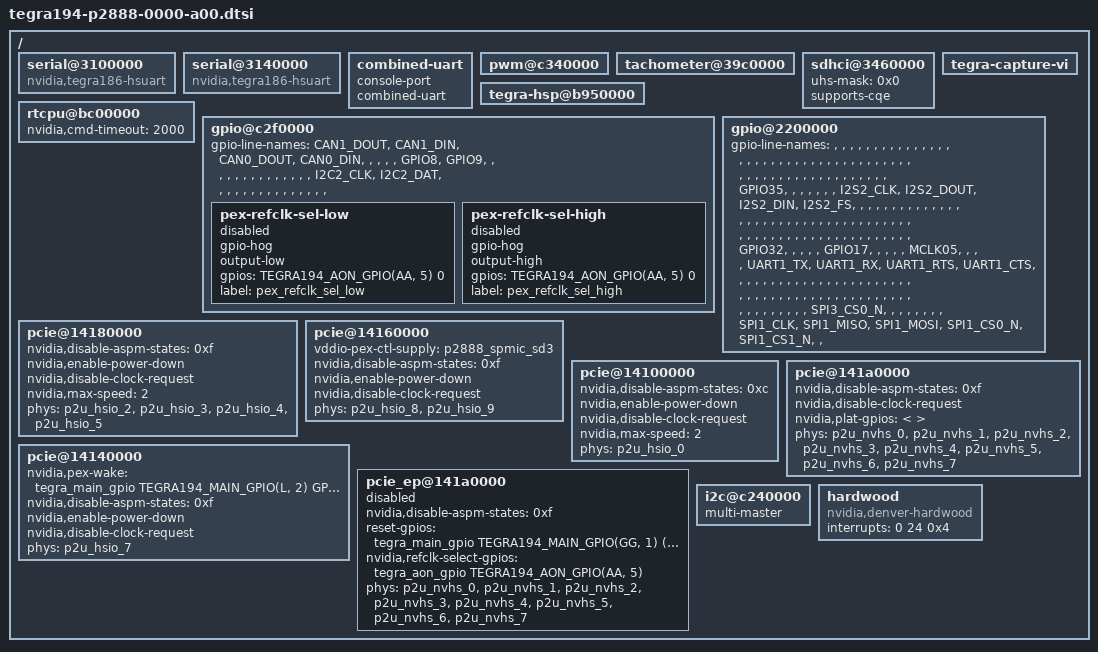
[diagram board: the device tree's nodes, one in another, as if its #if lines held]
/*
 * Copyright (c) 2017-2020, NVIDIA CORPORATION.  All rights reserved.
 *
 * This program is free software; you can redistribute it and/or modify it
 * under the terms and conditions of the GNU General Public License,
 * version 2, as published by the Free Software Foundation.
 *
 * This program is distributed in the hope it will be useful, but WITHOUT
 * ANY WARRANTY; without even the implied warranty of MERCHANTABILITY or
 * FITNESS FOR A PARTICULAR PURPOSE.  See the GNU General Public License for
 * more details.
 *
 * You should have received a copy of the GNU General Public License
 * along with this program.  If not, see <http://www.gnu.org/licenses/>.
 */

/*
 * T194 P2888-0000 common DTSI file.
 */

#include <t19x-common-modules/tegra194-cvm-p2888-0000-a00.dtsi>
#include "tegra194-eeprom-manager-p2888-0000.dtsi"
#include "tegra194-powermon-p2888.dtsi"
#include <dt-bindings/pinctrl/pinctrl-tegra.h>

/ {
/*
        pinmux@2430000 {
		pinctrl-names = "default", "drive", "unused";
		pinctrl-0 = <&pinmux_default>;
			
		pinmux_default: common {
		                dp_aux_ch0_hpd_pm0 {

                                nvidia,pins = "dp_aux_ch0_hpd_pm0";

                                nvidia,function = "rsvd1";

                                nvidia,pull = <TEGRA_PIN_PULL_NONE>;

                                nvidia,tristate = <TEGRA_PIN_ENABLE>;

                                nvidia,enable-input = <TEGRA_PIN_ENABLE>;

                                nvidia,io-high-voltage = <TEGRA_PIN_DISABLE>;

                                nvidia,lpdr = <TEGRA_PIN_DISABLE>;

                        };

                        dp_aux_ch1_hpd_pm1 {

                                nvidia,pins = "dp_aux_ch1_hpd_pm1";

                                nvidia,function = "rsvd1";

                                nvidia,pull = <TEGRA_PIN_PULL_NONE>;

                                nvidia,tristate = <TEGRA_PIN_ENABLE>;

                                nvidia,enable-input = <TEGRA_PIN_ENABLE>;

                                nvidia,io-high-voltage = <TEGRA_PIN_DISABLE>;

                                nvidia,lpdr = <TEGRA_PIN_DISABLE>;

                        };
                                               soc_gpio04_pp4 {

                                nvidia,pins = "soc_gpio04_pp4";

                                nvidia,function = "rsvd0";

                                nvidia,pull = <TEGRA_PIN_PULL_UP>;

                                nvidia,tristate = <TEGRA_PIN_ENABLE>;

                                nvidia,enable-input = <TEGRA_PIN_DISABLE>;

                                nvidia,lpdr = <TEGRA_PIN_DISABLE>;

                        };

                        soc_gpio54_pn1 {

                                nvidia,pins = "soc_gpio54_pn1";

                                nvidia,function = "rsvd0";

                                nvidia,pull = <TEGRA_PIN_PULL_UP>;

                                nvidia,tristate = <TEGRA_PIN_ENABLE>;

                                nvidia,enable-input = <TEGRA_PIN_ENABLE>;

                                nvidia,lpdr = <TEGRA_PIN_DISABLE>;

                        };

                        dap3_din_pt3 {

                                nvidia,pins = "dap3_din_pt3";

                                nvidia,function = "rsvd2";

                                nvidia,pull = <TEGRA_PIN_PULL_UP>;

                                nvidia,tristate = <TEGRA_PIN_ENABLE>;

                                nvidia,enable-input = <TEGRA_PIN_ENABLE>;

                                nvidia,lpdr = <TEGRA_PIN_DISABLE>;

                        };

                       

                        soc_gpio21_pq1 {

                                nvidia,pins = "soc_gpio21_pq1";

                                nvidia,function = "rsvd0";

                                nvidia,pull = <TEGRA_PIN_PULL_UP>;

                                nvidia,tristate = <TEGRA_PIN_ENABLE>;

                                nvidia,enable-input = <TEGRA_PIN_ENABLE>;

                                nvidia,lpdr = <TEGRA_PIN_DISABLE>;

                        };
                          dap1_sclk_ps0 {

                                nvidia,pins = "dap1_sclk_ps0";

                                nvidia,function = "i2s1";

                                nvidia,pull = <TEGRA_PIN_PULL_NONE>;

                                nvidia,tristate = <TEGRA_PIN_DISABLE>;

                                nvidia,enable-input = <TEGRA_PIN_ENABLE>;

                                nvidia,lpdr = <TEGRA_PIN_DISABLE>;

                        };

 

                        dap1_dout_ps1 {

                                nvidia,pins = "dap1_dout_ps1";

                                nvidia,function = "i2s1";

                                nvidia,pull = <TEGRA_PIN_PULL_NONE>;

                                nvidia,tristate = <TEGRA_PIN_DISABLE>;

                                nvidia,enable-input = <TEGRA_PIN_DISABLE>;

                                nvidia,lpdr = <TEGRA_PIN_DISABLE>;

                        };

 

                        dap1_din_ps2 {

                                nvidia,pins = "dap1_din_ps2";

                                nvidia,function = "i2s1";

                                nvidia,pull = <TEGRA_PIN_PULL_DOWN>;

                                nvidia,tristate = <TEGRA_PIN_ENABLE>;

                                nvidia,enable-input = <TEGRA_PIN_ENABLE>;

                                nvidia,lpdr = <TEGRA_PIN_DISABLE>;

                        };

 

                        dap1_fs_ps3 {

                                nvidia,pins = "dap1_fs_ps3";

                                nvidia,function = "i2s1";

                                nvidia,pull = <TEGRA_PIN_PULL_NONE>;

                                nvidia,tristate = <TEGRA_PIN_DISABLE>;

                                nvidia,enable-input = <TEGRA_PIN_ENABLE>;

                                nvidia,lpdr = <TEGRA_PIN_DISABLE>;

                        };
                         can1_dout_paa0 {

                                nvidia,pins = "can1_dout_paa0";

                                nvidia,function = "can1";

                                nvidia,pull = <TEGRA_PIN_PULL_NONE>;

                                nvidia,tristate = <TEGRA_PIN_DISABLE>;

                                nvidia,enable-input = <TEGRA_PIN_DISABLE>;

                        };

 

                        can1_din_paa1 {

                                nvidia,pins = "can1_din_paa1";

                                nvidia,function = "can1";

                                nvidia,pull = <TEGRA_PIN_PULL_NONE>;

                                nvidia,tristate = <TEGRA_PIN_ENABLE>;

                                nvidia,enable-input = <TEGRA_PIN_ENABLE>;

                        };

 

                        can0_dout_paa2 {

                                nvidia,pins = "can0_dout_paa2";

                                nvidia,function = "can0";

                                nvidia,pull = <TEGRA_PIN_PULL_NONE>;

                                nvidia,tristate = <TEGRA_PIN_DISABLE>;

                                nvidia,enable-input = <TEGRA_PIN_DISABLE>;

                        };

 

                        can0_din_paa3 {

                                nvidia,pins = "can0_din_paa3";

                                nvidia,function = "can0";

                                nvidia,pull = <TEGRA_PIN_PULL_NONE>;

                                nvidia,tristate = <TEGRA_PIN_ENABLE>;

                                nvidia,enable-input = <TEGRA_PIN_ENABLE>;

                        };
                        can0_wake_paa6 {

                                nvidia,pins = "can0_wake_paa6";

                                nvidia,function = "rsvd0";

                                nvidia,pull = <TEGRA_PIN_PULL_DOWN>;

                                nvidia,tristate = <TEGRA_PIN_ENABLE>;

                                nvidia,enable-input = <TEGRA_PIN_ENABLE>;

                        };
                        
                        gen1_i2c_scl_pi3 {

                                nvidia,pins = "gen1_i2c_scl_pi3";

                                nvidia,function = "i2c1";

                                nvidia,pull = <TEGRA_PIN_PULL_NONE>;

                                nvidia,tristate = <TEGRA_PIN_DISABLE>;

                                nvidia,enable-input = <TEGRA_PIN_ENABLE>;

                                nvidia,io-high-voltage = <TEGRA_PIN_DISABLE>;

                                nvidia,lpdr = <TEGRA_PIN_DISABLE>;

                        };

 

                        gen1_i2c_sda_pi4 {

                                nvidia,pins = "gen1_i2c_sda_pi4";

                                nvidia,function = "i2c1";

                                nvidia,pull = <TEGRA_PIN_PULL_NONE>;

                                nvidia,tristate = <TEGRA_PIN_DISABLE>;

                                nvidia,enable-input = <TEGRA_PIN_ENABLE>;

                                nvidia,io-high-voltage = <TEGRA_PIN_DISABLE>;

                                nvidia,lpdr = <TEGRA_PIN_DISABLE>;

                        };
			spi1_sck_pz3 {
				nvidia,pins = "spi1_sck_pz3";
				nvidia,function = "spi1";
				nvidia,lpdr = <0x0>;
				nvidia,enable-input = <0x1>;
				nvidia,tristate = <0x0>;
				nvidia,pull = <0x2>;
			};

			spi1_miso_pz4 {
				nvidia,pins = "spi1_miso_pz4";
				nvidia,function = "spi1";
				nvidia,lpdr = <0x0>;
				nvidia,enable-input = <0x1>;
				nvidia,tristate = <0x0>;
				nvidia,pull = <0x2>;
			};

			spi1_mosi_pz5 {
				nvidia,pins = "spi1_mosi_pz5";
				nvidia,function = "spi1";
				nvidia,lpdr = <0x0>;
				nvidia,enable-input = <0x1>;
				nvidia,tristate = <0x0>;
				nvidia,pull = <0x2>;
			};

			spi1_cs0_pz6 {
				nvidia,pins = "spi1_cs0_pz6";
				nvidia,function = "spi1";
				nvidia,lpdr = <0x0>;
				nvidia,enable-input = <0x1>;
				nvidia,tristate = <0x0>;
				nvidia,pull = <0x2>;
			};

			spi1_cs1_pz7 {
				nvidia,pins = "spi1_cs1_pz7";
				nvidia,function = "spi1";
				nvidia,lpdr = <0x0>;
				nvidia,enable-input = <0x1>;
				nvidia,tristate = <0x0>;
				nvidia,pull = <0x2>;
			};

			can1_stb_pbb0 {
				nvidia,pins = "can1_stb_pbb0";
				nvidia,function = "rsvd0";
				nvidia,pull = <TEGRA_PIN_PULL_NONE>;
				nvidia,tristate = <TEGRA_PIN_ENABLE>;
				nvidia,enable-input = <TEGRA_PIN_ENABLE>;
			};
			
			can0_en_paa5 {
				nvidia,pins = "can0_en_paa5";
				nvidia,function = "rsvd0";
				nvidia,pull = <TEGRA_PIN_PULL_NONE>;
				nvidia,tristate = <TEGRA_PIN_ENABLE>;
				nvidia,enable-input = <TEGRA_PIN_ENABLE>;
			};
			
			can1_wake_pbb2 {
				nvidia,pins = "can1_wake_pbb2";
				nvidia,function = "rsvd0";
				nvidia,pull = <TEGRA_PIN_PULL_NONE>;
				nvidia,tristate = <TEGRA_PIN_ENABLE>;
				nvidia,enable-input = <TEGRA_PIN_ENABLE>;
			};
			

			soc_gpio33_pt0 {
				nvidia,pins = "soc_gpio33_pt0";
				nvidia,function = "rsvd0";
				nvidia,pull = <TEGRA_PIN_PULL_UP>;
				nvidia,tristate = <TEGRA_PIN_ENABLE>;
				nvidia,enable-input = <TEGRA_PIN_ENABLE>;
				nvidia,lpdr = <TEGRA_PIN_DISABLE>;
			};
			
			
			dap3_fs_pt4 {
				nvidia,pins = "dap3_fs_pt4";
				nvidia,function = "rsvd2";
				nvidia,pull = <TEGRA_PIN_PULL_UP>;
				nvidia,tristate = <TEGRA_PIN_ENABLE>;
				nvidia,enable-input = <TEGRA_PIN_ENABLE>;
				nvidia,lpdr = <TEGRA_PIN_DISABLE>;
			};
			
			soc_gpio40_pq4 {
				nvidia,pins = "soc_gpio40_pq4";
				nvidia,function = "rsvd2";
				nvidia,pull = <TEGRA_PIN_PULL_UP>;
				nvidia,tristate = <TEGRA_PIN_ENABLE>;
				nvidia,enable-input = <TEGRA_PIN_ENABLE>;
				nvidia,io-high-voltage = <TEGRA_PIN_DISABLE>;
				nvidia,lpdr = <TEGRA_PIN_DISABLE>;
			};
			
			soc_gpio53_pn0 {
				nvidia,pins = "soc_gpio53_pn0";
				nvidia,function = "rsvd0";
				nvidia,pull = <TEGRA_PIN_PULL_DOWN>;
				nvidia,tristate = <TEGRA_PIN_DISABLE>;
				nvidia,enable-input = <TEGRA_PIN_ENABLE>;
				nvidia,lpdr = <TEGRA_PIN_DISABLE>;
			};
			
			safe_state_pee0 {
				nvidia,pins = "safe_state_pee0";
				nvidia,function = "rsvd1";
				nvidia,pull = <TEGRA_PIN_PULL_UP>;
				nvidia,tristate = <TEGRA_PIN_ENABLE>;
				nvidia,enable-input = <TEGRA_PIN_ENABLE>;
				nvidia,io-high-voltage = <TEGRA_PIN_DISABLE>;
				nvidia,lpdr = <TEGRA_PIN_DISABLE>;
			};
			
			
			soc_gpio50_pm5 {
				nvidia,pins = "soc_gpio50_pm5";
				nvidia,function = "rsvd0";
				nvidia,pull = <TEGRA_PIN_PULL_UP>;
				nvidia,tristate = <TEGRA_PIN_ENABLE>;
				nvidia,enable-input = <TEGRA_PIN_ENABLE>;
				nvidia,lpdr = <TEGRA_PIN_DISABLE>;
			};
			
		        usb_vbus_en1_pz2 {
				nvidia,pins = "usb_vbus_en1_pz2";
				nvidia,function = "rsvd1";
				nvidia,pull = <TEGRA_PIN_PULL_NONE>;
				nvidia,tristate = <TEGRA_PIN_ENABLE>;
				nvidia,enable-input = <TEGRA_PIN_ENABLE>;
				nvidia,io-high-voltage = <TEGRA_PIN_DISABLE>;
				nvidia,lpdr = <TEGRA_PIN_DISABLE>;
			};

			soc_gpio02_pg2 {
				nvidia,pins = "soc_gpio02_pg2";
				nvidia,function = "rsvd0";
				nvidia,pull = <TEGRA_PIN_PULL_UP>;
				nvidia,tristate = <TEGRA_PIN_ENABLE>;
				nvidia,enable-input = <TEGRA_PIN_ENABLE>;
				nvidia,lpdr = <TEGRA_PIN_DISABLE>;
			};
			
			dp_aux_ch3_hpd_pm3 {
				nvidia,pins = "dp_aux_ch3_hpd_pm3";
				nvidia,function = "rsvd2";
				nvidia,pull = <TEGRA_PIN_PULL_UP>;
				nvidia,tristate = <TEGRA_PIN_ENABLE>;
				nvidia,enable-input = <TEGRA_PIN_ENABLE>;
				nvidia,io-high-voltage = <TEGRA_PIN_DISABLE>;
			};
			
			soc_gpio43_pq7 {
				nvidia,pins = "soc_gpio43_pq7";
				nvidia,function = "rsvd2";
				nvidia,pull = <TEGRA_PIN_PULL_UP>;
				nvidia,tristate = <TEGRA_PIN_ENABLE>;
				nvidia,enable-input = <TEGRA_PIN_ENABLE>;
				nvidia,io-high-voltage = <TEGRA_PIN_DISABLE>;
				nvidia,lpdr = <TEGRA_PIN_DISABLE>;
			};

		};
	};
	
	*/
	serial@3100000 {
		compatible = "nvidia,tegra186-hsuart";
		status = "okay";
	};

	serial@3140000 {
		compatible = "nvidia,tegra186-hsuart";
		status = "okay";
	};

	combined-uart {
		console-port;
		combined-uart;
		status = "okay";
	};

	pwm@c340000 {
		status = "okay";
	};

	tachometer@39c0000 {
		status = "okay";
	};

	sdhci@3460000 {
		uhs-mask = <0x0>;
#if TEGRA_SDMMC_VERSION >= DT_VERSION_2
		supports-cqe;
#else
		nvidia,enable-hwcq;
#endif
		status = "okay";
	};

	tegra-hsp@b950000 {
		status = "okay";
	};

	rtcpu@bc00000 {
		status = "okay";
		nvidia,cmd-timeout = <2000>;
	};

	tegra-capture-vi {
		status = "okay";
	};

#if TEGRA_PCIE_VERSION < DT_VERSION_2
	gpio@c2f0000 {
		/* gpio-name for 40-pin header, gpio-name given as COL(10) x ROW(4) */
		gpio-line-names = "CAN1_DOUT",   "CAN1_DIN",     "CAN0_DOUT",     "CAN0_DIN",     "",     "",     "",     "",     "GPIO8",     "GPIO9",
		"",     "",     "",    "",    "",     "",     "",    "",    "",     "",
		"",     "",     "",     "I2C2_CLK",     "I2C2_DAT",     "",     "",     "",     "",     "",
		"",     "",     "",    "",    "",     "",     "",    "",    "",     "";

		pex-refclk-sel-low {
			gpio-hog;
			output-low;
			gpios = <TEGRA194_AON_GPIO(AA, 5) 0>;
			label = "pex_refclk_sel_low";
			status = "disabled";
		};

		pex-refclk-sel-high {
			gpio-hog;
			output-high;
			gpios = <TEGRA194_AON_GPIO(AA, 5) 0>;
			label = "pex_refclk_sel_high";
			status = "disabled";
		};
	};
#endif

	gpio@2200000 {
		/* gpio-name for 40-pin header, gpio-name given as COL(10) x ROW(21) */
		gpio-line-names = "",   "",     "",     "",     "",     "",     "",     "",     "",     "",
		"",     "",     "",    "",    "",     "",     "",    "",    "",     "",
		"",     "",     "",     "",     "",     "",     "",     "",     "",     "",
		"",     "",     "",     "",     "",     "",     "",     "",     "",      "",
		"",     "",     "",     "",     "",     "",     "",     "",     "",     "",
		"",    "",    "",     "",     "",     "",     "GPIO35",     "",     "",     "",
		"",     "",     "",     "I2S2_CLK",     "I2S2_DOUT",     "I2S2_DIN",     "I2S2_FS",     "",     "",     "",
		"",     "",     "",     "",     "",     "",     "",    "",    "",   "",
		"",     "",     "",     "",     "",     "",     "",     "",     "",     "",
		"",     "",     "",     "",     "",     "",     "",     "",     "",     "",
		"",     "",     "",     "",     "",     "",     "",     "",     "",     "",
		"",     "",     "",     "",     "",     "",     "",     "",     "",     "",
		"",     "",     "",     "",     "GPIO32",     "",     "",     "",     "",     "GPIO17",
		"",     "",     "",     "",     "MCLK05",     "",     "",     "",     "UART1_TX",     "UART1_RX",
		"UART1_RTS",     "UART1_CTS",     "",     "",     "",     "",     "",     "",     "",     "",
		"",     "",     "",     "",     "",     "",     "",     "",     "",     "",
		"",     "",     "",     "",     "",     "",     "",     "",     "",   "",
		"",     "",     "",     "",     "",     "",     "",     "",     "",   "",
		"",     "",     "",     "",     "",     "",     "",     "",     "",   "",
		"",     "",     "",     "",     "",     "SPI3_CS0_N",     "",     "",     "",   "",
		"",     "",     "",     "SPI1_CLK",     "SPI1_MISO",     "SPI1_MOSI",     "SPI1_CS0_N",     "SPI1_CS1_N",     "",     "";
	};

	pcie@14180000 {
		status = "okay";

		nvidia,disable-aspm-states = <0xf>;
		nvidia,enable-power-down;
		nvidia,disable-clock-request;
		nvidia,max-speed = <2>;
#if TEGRA_PCIE_VERSION >= DT_VERSION_2
		phys = <&p2u_hsio_2>, <&p2u_hsio_3>, <&p2u_hsio_4>,
		       <&p2u_hsio_5>;
		phy-names = "p2u-0", "p2u-1", "p2u-2", "p2u-3";
#else
		phys = <&p2u_2>,
		       <&p2u_3>,
		       <&p2u_4>,
		       <&p2u_5>;
		phy-names = "pcie-p2u-0", "pcie-p2u-1", "pcie-p2u-2", "pcie-p2u-3";
#endif
	};
	
	pcie@14160000 {
		status = "okay";
		vddio-pex-ctl-supply = <&p2888_spmic_sd3>;
		nvidia,disable-aspm-states = <0xf>;
		nvidia,enable-power-down;
		nvidia,disable-clock-request;
		//nvidia,disable-clock-request;
		//nvidia,max-speed = <2>;
#if TEGRA_PCIE_VERSION >= DT_VERSION_2
		phys = <&p2u_hsio_8>, <&p2u_hsio_9>;
		phy-names = "p2u-0", "p2u-1";
#else
		phys = <&p2u_8>,
		       <&p2u_9>;
		phy-names = "pcie-p2u-0", "pcie-p2u-1";
#endif
	};
	
	pcie@14100000 {
		status = "okay";

		nvidia,disable-aspm-states = <0xc>;
		nvidia,enable-power-down;
		nvidia,disable-clock-request;

		nvidia,max-speed = <2>;
#if TEGRA_PCIE_VERSION >= DT_VERSION_2
		phys = <&p2u_hsio_0>;
		phy-names = "p2u-0";
#else
		phys = <&p2u_0>;
		phy-names = "pcie-p2u-0";
#endif
	};

	pcie@14140000 {
		status = "okay";

		nvidia,pex-wake = <&tegra_main_gpio TEGRA194_MAIN_GPIO(L, 2)
					GPIO_ACTIVE_HIGH>;
		nvidia,disable-aspm-states = <0xf>;
		nvidia,enable-power-down;
		nvidia,disable-clock-request;
#if TEGRA_PCIE_VERSION >= DT_VERSION_2
		phys = <&p2u_hsio_7>;
		phy-names = "p2u-0";
#else
		phys = <&p2u_7>;
		phy-names = "pcie-p2u-0";
#endif
	};

	pcie@141a0000 {
		status = "okay";

		nvidia,disable-aspm-states = <0xf>;
		//nvidia,enable-power-down;
		nvidia,disable-clock-request;

		nvidia,plat-gpios =
			<
		       /*&tegra_main_gpio TEGRA194_MAIN_GPIO(Y, 4) GPIO_ACTIVE_HIGH */ /* I2C */
			>;
#if TEGRA_PCIE_VERSION >= DT_VERSION_2
		phys = <&p2u_nvhs_0>, <&p2u_nvhs_1>, <&p2u_nvhs_2>,
		       <&p2u_nvhs_3>, <&p2u_nvhs_4>, <&p2u_nvhs_5>,
		       <&p2u_nvhs_6>, <&p2u_nvhs_7>;

		phy-names = "p2u-0", "p2u-1", "p2u-2", "p2u-3", "p2u-4",
			    "p2u-5", "p2u-6", "p2u-7";
#else
		phys = <&p2u_12>,
		       <&p2u_13>,
		       <&p2u_14>,
		       <&p2u_15>,
		       <&p2u_16>,
		       <&p2u_17>,
		       <&p2u_18>,
		       <&p2u_19>;

		phy-names = "pcie-p2u-0", "pcie-p2u-1", "pcie-p2u-2", "pcie-p2u-3",
					"pcie-p2u-4", "pcie-p2u-5", "pcie-p2u-6", "pcie-p2u-7";
#endif
	};

	pcie_ep@141a0000 {
		status = "disabled";

		nvidia,disable-aspm-states = <0xf>;

#if TEGRA_PCIE_VERSION >= DT_VERSION_2
		reset-gpios = <&tegra_main_gpio TEGRA194_MAIN_GPIO(GG, 1) GPIO_ACTIVE_LOW>;

		nvidia,refclk-select-gpios = <&tegra_aon_gpio TEGRA194_AON_GPIO(AA, 5)
					      GPIO_ACTIVE_HIGH>;

		phys = <&p2u_nvhs_0>, <&p2u_nvhs_1>, <&p2u_nvhs_2>,
		       <&p2u_nvhs_3>, <&p2u_nvhs_4>, <&p2u_nvhs_5>,
		       <&p2u_nvhs_6>, <&p2u_nvhs_7>;

		phy-names = "p2u-0", "p2u-1", "p2u-2", "p2u-3", "p2u-4",
			    "p2u-5", "p2u-6", "p2u-7";
#else
		phys = <&p2u_12>, <&p2u_13>, <&p2u_14>, <&p2u_15>,
			<&p2u_16>, <&p2u_17>, <&p2u_18>, <&p2u_19>;

		phy-names = "pcie-p2u-0", "pcie-p2u-1", "pcie-p2u-2", "pcie-p2u-3",
				"pcie-p2u-4", "pcie-p2u-5", "pcie-p2u-6", "pcie-p2u-7";

		nvidia,pex-rst-gpio = <&tegra_main_gpio TEGRA194_MAIN_GPIO(GG, 1)
					GPIO_ACTIVE_LOW>;
#endif
	};

	i2c@c240000 {
		multi-master;
	};

	hardwood {
		compatible = "nvidia,denver-hardwood";
		interrupts = <0 24 0x4>;
	};
};
